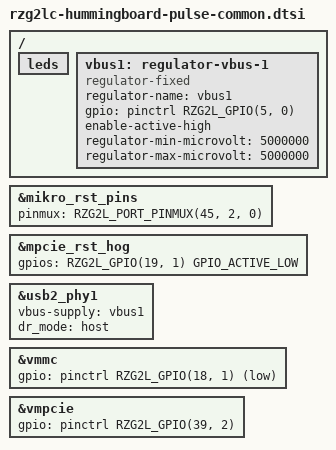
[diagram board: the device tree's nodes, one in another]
// SPDX-License-Identifier: (GPL-2.0-only OR BSD-2-Clause)
/*
 * Copyright 2025 Josua Mayer <josua@solid-run.com>
 */

#include "rzg2l-hummingboard-pulse-common.dtsi"

/ {
	/delete-node/ rfkill-mpcie-wifi;

	leds {
		/* led gpios conflict with RZ/G2LC SoM bluetooth */
		/delete-node/ led-1;
		/delete-node/ led-2;
		/delete-node/ led-3;
		/delete-node/ led-4;
	};

	vbus1: regulator-vbus-1 {
		compatible = "regulator-fixed";
		regulator-name = "vbus1";
		gpio = <&pinctrl RZG2L_GPIO(5, 0) GPIO_ACTIVE_HIGH>;
		enable-active-high;
		regulator-min-microvolt = <5000000>;
		regulator-max-microvolt = <5000000>;
	};
};

&mikro_rst_pins {
	pinmux = <RZG2L_PORT_PINMUX(45, 2, 0)>; /* P45_2 */
};

&mpcie_rst_hog {
	gpios = <RZG2L_GPIO(19, 1) GPIO_ACTIVE_LOW>;
};

&usb2_phy1 {
	/* RZ/G2LC SoM vbus gpio does not have native vbus function */
	/delete-property/ pinctrl-0;
	/delete-property/ pinctrl-names;
	vbus-supply = <&vbus1>;
	dr_mode = "host";
};

&vmmc {
	gpio = <&pinctrl RZG2L_GPIO(18, 1) GPIO_ACTIVE_LOW>;
};

&vmpcie {
	/*
	 * G2LC SoM v1.2 moved this IO from J7-28 (CON4-12)
	 * to J7-18 (this regulator).
	 * There are no known users of CON4-12 and thus no need
	 * to differentiate here between SoM v1.1 and v1.2.
	 */
	gpio = <&pinctrl RZG2L_GPIO(39, 2) GPIO_ACTIVE_HIGH>;
};
